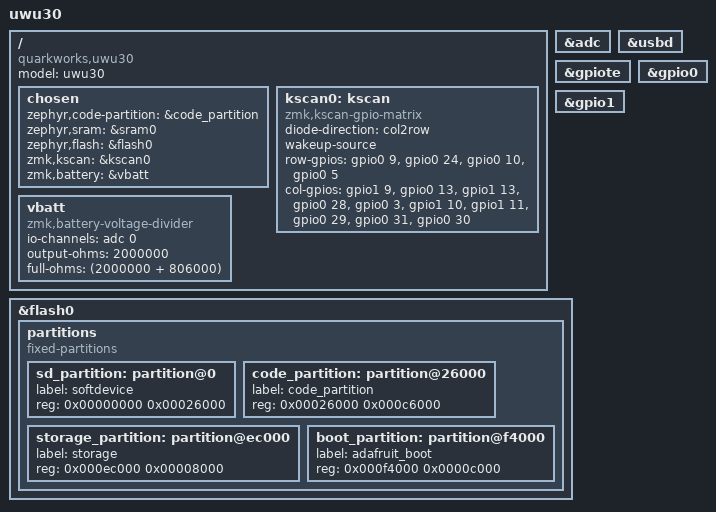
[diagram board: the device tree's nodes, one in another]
/*
 * Copyright (c) 2025 Brandon Beltran
 *
 * SPDX-License-Identifier: MIT
 */

/dts-v1/;

#include <nordic/nrf52840_qiaa.dtsi>

#include "uwu30-transforms.dtsi"
#include "uwu30-layouts.dtsi"

/ {
    model = "uwu30";
    compatible = "quarkworks,uwu30";

    chosen {
        zephyr,code-partition = &code_partition;
        zephyr,sram = &sram0;
        zephyr,flash = &flash0;
        zmk,kscan = &kscan0;
        zmk,battery = &vbatt;
    };

    kscan0: kscan {
        compatible = "zmk,kscan-gpio-matrix";
        diode-direction = "col2row";
        wakeup-source;

        row-gpios
            = <&gpio0  9 (GPIO_ACTIVE_HIGH | GPIO_PULL_DOWN)>
            , <&gpio0 24 (GPIO_ACTIVE_HIGH | GPIO_PULL_DOWN)>
            , <&gpio0 10 (GPIO_ACTIVE_HIGH | GPIO_PULL_DOWN)>
            , <&gpio0  5 (GPIO_ACTIVE_HIGH | GPIO_PULL_DOWN)>
            ;
        col-gpios
            = <&gpio1  9 GPIO_ACTIVE_HIGH>
            , <&gpio0 13 GPIO_ACTIVE_HIGH>
            , <&gpio1 13 GPIO_ACTIVE_HIGH>
            , <&gpio0 28 GPIO_ACTIVE_HIGH>
            , <&gpio0  3 GPIO_ACTIVE_HIGH>
            , <&gpio1 10 GPIO_ACTIVE_HIGH>
            , <&gpio1 11 GPIO_ACTIVE_HIGH>
            , <&gpio0 29 GPIO_ACTIVE_HIGH>
            , <&gpio0 31 GPIO_ACTIVE_HIGH>
            , <&gpio0 30 GPIO_ACTIVE_HIGH>
            ;
    };

    vbatt: vbatt {
        compatible = "zmk,battery-voltage-divider";
        io-channels = <&adc 0>;
        output-ohms = <2000000>;
        full-ohms = <(2000000 + 806000)>;
    };
};

&adc {
    status = "okay";
};

zephyr_udc0: &usbd {
    status = "okay";
};

&gpiote {
    status = "okay";
};

&gpio0 {
    status = "okay";
};

&gpio1 {
    status = "okay";
};


&flash0 {
    /*
     * For more information, see:
     * http://docs.zephyrproject.org/latest/devices/dts/flash_partitions.html
     */
    partitions {
        compatible = "fixed-partitions";
        #address-cells = <1>;
        #size-cells = <1>;

        sd_partition: partition@0 {
            label = "softdevice";
            reg = <0x00000000 0x00026000>;
        };
        code_partition: partition@26000 {
            label = "code_partition";
            reg = <0x00026000 0x000c6000>;
        };

        /*
         * The flash starting at 0x000ec000 and ending at
         * 0x000f3fff is reserved for use by the application.
         */

        /*
         * Storage partition will be used by FCB/LittleFS/NVS
         * if enabled.
         */
        storage_partition: partition@ec000 {
            label = "storage";
            reg = <0x000ec000 0x00008000>;
        };

        boot_partition: partition@f4000 {
            label = "adafruit_boot";
            reg = <0x000f4000 0x0000c000>;
        };
    };
};
